AUTOSAR XML (schema 00048)
package /HuaweiMDC/PlatformApplication/FmApplication/Execution
  executable fm
    root sw component prototype fm: application-type=fm
  executable fm_sea
    root sw component prototype fm: application-type=fm
package /HuaweiMDC/PlatformApplication/FmApplication/SwcComponent
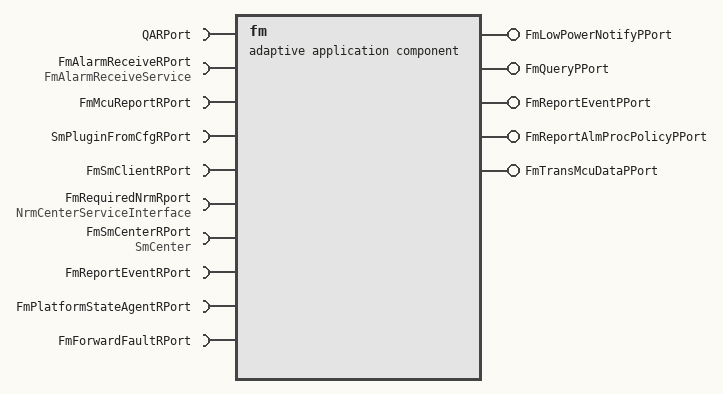
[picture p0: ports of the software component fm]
  adaptive application sw component type fm
    provide port FmLowPowerNotifyPPort
    provide port FmQueryPPort
    provide port FmReportEventPPort
    5 x require port:
      QARPort
      FmAlarmReceiveRPort: required-interface=FmAlarmReceiveService
      FmMcuReportRPort
      SmPluginFromCfgRPort
      FmSmClientRPort
    provide port FmReportAlmProcPolicyPPort
    require port FmRequiredNrmRport: required-interface=NrmCenterServiceInterface
    provide port FmTransMcuDataPPort
    4 x require port:
      FmSmCenterRPort: required-interface=SmCenter
      FmReportEventRPort
      FmPlatformStateAgentRPort
      FmForwardFaultRPort
  composition sw component type fm_diag
    component fm: type=fm
    component diag_agent: type=diag_agent
